AUTOSAR XML (schema 4-2-1)
package /MyDataTypes
  base type myuint8: category=FIXED_LENGTH, base-type-size=8, base-type-encoding=NONE, native-declaration=unsigned char
  impl type myuint8: category=VALUE, base-type=myuint8, range phys 0..255, raw 0..255
package /Interfaces
  sender receiver interface SendRecInterface_DoorState
    data DoorState: type=myuint8
  client server interface ClServInterface_Led
    operation Led: possible-error=[ERROR_OK, ERROR_NOT_OK]
      arg LedState: type=myuint8, direction=IN
    error ERROR_OK: error-code=0
    error ERROR_NOT_OK: error-code=1
package /SWCs
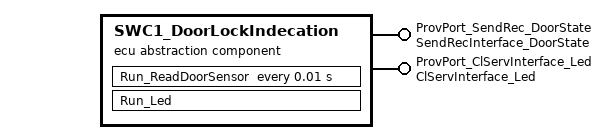
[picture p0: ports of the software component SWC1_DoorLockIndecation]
  ecu abstraction sw component type SWC1_DoorLockIndecation
    provide port ProvPort_SendRec_DoorState: provided-interface=SendRecInterface_DoorState
    provide port ProvPort_ClServInterface_Led: provided-interface=ClServInterface_Led
    behavior Beh_SWC1_DoorLockIndecation
      timing event TimEvent_10ms: start-on-event=Run_ReadDoorSensor, period=0.01
      operation invoked event OperInvkEvent_Led: start-on-event=Run_Led, operation=ProvPort_ClServInterface_Led.Led
      runnable Run_ReadDoorSensor
        data-write-access:
          access DataAcc_DoorState: accessed-variable=ProvPort_SendRec_DoorState.DoorState
      runnable Run_Led
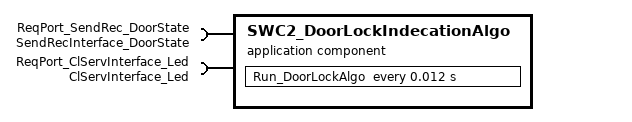
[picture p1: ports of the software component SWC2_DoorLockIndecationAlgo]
  application sw component type SWC2_DoorLockIndecationAlgo
    require port ReqPort_SendRec_DoorState: required-interface=SendRecInterface_DoorState
    require port ReqPort_ClServInterface_Led: required-interface=ClServInterface_Led
    behavior Beh_SWC2_DoorLockIndecationAlgo
      timing event TimEvent_12ms: start-on-event=Run_DoorLockAlgo, period=0.012
      runnable Run_DoorLockAlgo
        data-read-access:
          access DataAcc_DoorState: accessed-variable=ReqPort_SendRec_DoorState.DoorState
        sync call ServerCall: operation=ReqPort_ClServInterface_Led.Led
